# Cortex_M52 register map
Vendor: Arm Ltd.; Series: ARMv8.1-M Mainline; File version: 1.0.0
CPU: other r0p0, little endian, MPU, FPU, double-precision FPU, DSP, 8 interrupt priority bits
Registers are 32-bit, read-write, reset 0x0 unless marked. A register's access mark holds for its fields unless they carry their own. Offsets are from the block's base; [hi:lo] are bit positions; {n}, {i} and the like mark numbered series.

## PMU — Performance Monitoring Unit (ARMv8.1-M): a 32-bit cycle counter and up to 8 (architecturally 31) 16-bit event counters selecting from the PMU event list (instructions, cache refills, branch mispredictions, MVE activity ...), with overflow interrupt/halt.
Base 0xE0003000
{0x0+4i} EVCNTR{i} (i=0..7) — Event Counter n: 16-bit count of the event selected in EVTYPERn. Only NUM_CNTS counters exist (8 on Cortex-M55/M85); the rest read as zero.
  [15:0] CNT — Event count (16 bits on Cortex-M55/M85; an overflow sets OVSSET bit n).
0x7C CCNTR — Cycle Counter: 32-bit processor cycle count while CTRL.ENABLE = 1 and CYCCNT_DISABLE = 0.
  [31:0] CCNT — Cycle count.
{0x400+4i} EVTYPER{i} (i=0..7) — Event Type Register n: the event number counter n counts (see the PMU event list in the core TRM).
  [15:0] EVENTTOCNT — Event number to count. Common events: 0x0000 SW_INCR, 0x0001 L1I_CACHE_REFILL, 0x0003 L1D_CACHE_REFILL, 0x0004 L1D_CACHE, 0x0008 INST_RETIRED, 0x0010 BR_MIS_PRED, 0x0011 CPU_CYCLES, 0x0012 BR_PRED, 0x0014 L1I_CACHE, 0x0023 STALL_FRONTEND, 0x0024 STALL_BACKEND, 0x0100-0x01xx MVE_* (see the core TRM).
0x47C CCFILTR — Cycle Counter Filter Register: reserved (no filtering on M-profile).
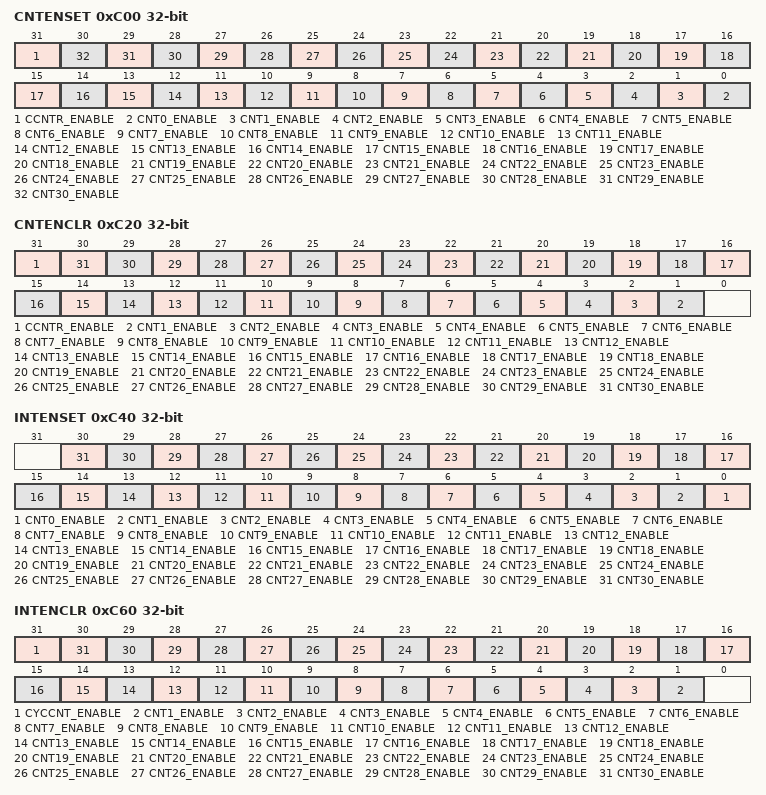
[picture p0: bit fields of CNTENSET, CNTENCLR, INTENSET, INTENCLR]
0xC00 CNTENSET — Count Enable Set Register: write 1 to enable a counter; reads the enable state of every counter.
  [31] CCNTR_ENABLE — Cycle counter: write 1 to enable; reads 1 if enabled.
  [n] CNT{n}_ENABLE (n=0..30) — Event counter {n}: write 1 to enable; reads 1 if enabled.
0xC20 CNTENCLR — Count Enable Clear Register: write 1 to disable a counter; reads the enable state.
  [31] CCNTR_ENABLE — Cycle counter: write 1 to disable; reads 1 if enabled.
  [n] CNT{n}_ENABLE (n=1..30) — Event counter {n}: write 1 to disable; reads 1 if enabled.
0xC40 INTENSET — Interrupt Enable Set Register: write 1 to enable the overflow interrupt/debug event of a counter; reads the enable state.
  [n] CNT{n}_ENABLE (n=0..30) — Event counter {n}: write 1 to enable its overflow interrupt (PMU_IRQ) / debug event; reads 1 if enabled.
0xC60 INTENCLR — Interrupt Enable Clear Register: write 1 to disable the overflow interrupt of a counter.
  [31] CYCCNT_ENABLE — Cycle counter: write 1 to disable its overflow interrupt; reads 1 if enabled.
  [n] CNT{n}_ENABLE (n=1..30) — Event counter {n}: write 1 to disable its overflow interrupt; reads 1 if enabled.
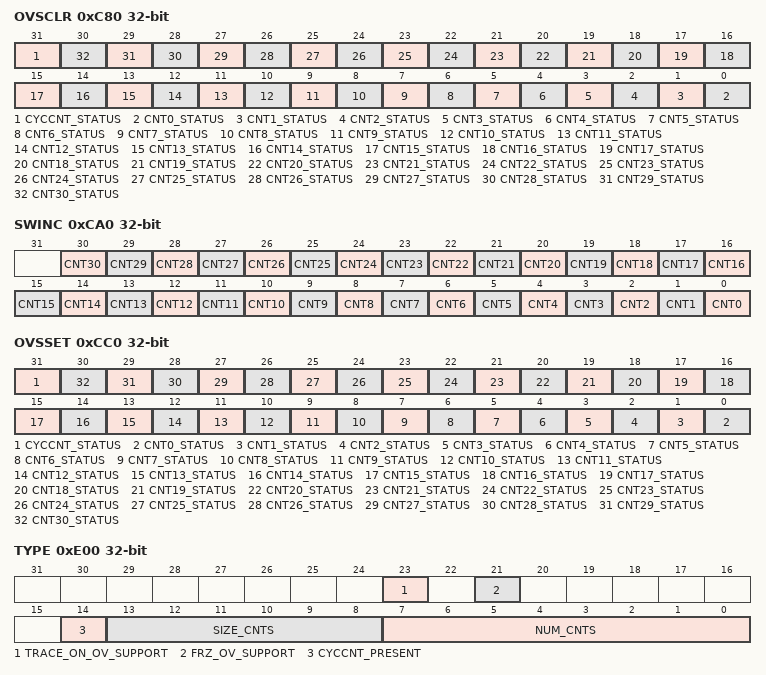
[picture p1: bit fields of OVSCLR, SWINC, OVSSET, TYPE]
0xC80 OVSCLR — Overflow Flag Status Clear Register: reads the overflow flags; write 1 to clear a flag.
  [31] CYCCNT_STATUS — Cycle counter overflowed; write 1 to clear the flag.
  [n] CNT{n}_STATUS (n=0..30) — Event counter {n} overflowed; write 1 to clear the flag.
0xCA0 SWINC — Software Increment Register: write 1 to increment a counter that is counting the SW_INCR event (0x0000).
  [n] CNT{n} (n=0..30) — Write 1 to increment event counter {n} if it counts SW_INCR (event 0x0000).
0xCC0 OVSSET — Overflow Flag Status Set Register: reads the overflow flags; write 1 to set a flag (testing).
  [31] CYCCNT_STATUS — Cycle counter overflow flag; write 1 to set it.
  [n] CNT{n}_STATUS (n=0..30) — Event counter {n} overflow flag; write 1 to set it.
0xE00 TYPE — PMU Type Register: how many counters exist, their size, and which options are supported. Read-only.
  [23] TRACE_ON_OV_SUPPORT — 1 = trace-on-overflow (CTRL.TRACE_ON_OV) is supported.
  [21] FRZ_OV_SUPPORT — 1 = freeze-on-overflow (CTRL.FRZ_ON_OV) is supported.
  [14] CYCCNT_PRESENT — 1 = the cycle counter CCNTR is implemented.
  [13:8] SIZE_CNTS — Event counter size - 1 in bits (15 = 16-bit counters).
  [7:0] NUM_CNTS — Number of event counters implemented (8 on Cortex-M55/M85/M52).
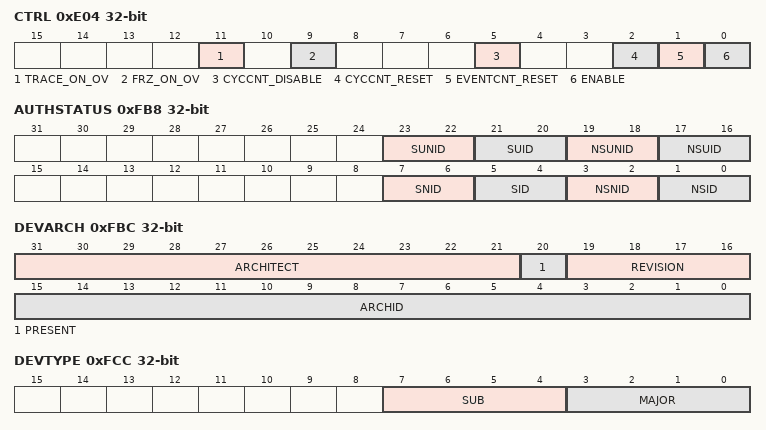
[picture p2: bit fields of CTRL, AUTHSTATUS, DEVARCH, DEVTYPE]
0xE04 CTRL — PMU Control Register: global enable, counter resets, cycle counter disable, freeze/trace on overflow.
  [11] TRACE_ON_OV — Trace on overflow: 1 = a counter overflow emits a trace (ITM/ETM) event.
  [9] FRZ_ON_OV — Freeze on overflow: 1 = all counters stop when any counter overflows, so a snapshot can be read.
  [5] CYCCNT_DISABLE — 1 = the cycle counter is disabled even when ENABLE = 1.
  [2] CYCCNT_RESET — Write 1 to reset CCNTR to 0. Reads as 0.
  [1] EVENTCNT_RESET — Write 1 to reset every event counter to 0. Reads as 0.
  [0] ENABLE — Global enable: 0 = all counters stop (their values are kept).
0xFB8 AUTHSTATUS — Authentication Status Register: which debug/trace permissions currently apply to the PMU.
  [23:22] SUNID — Secure unprivileged non-invasive debug: 2 = disabled, 3 = enabled.
  [21:20] SUID — Secure unprivileged invasive debug: 2 = disabled, 3 = enabled.
  [19:18] NSUNID — Non-secure unprivileged non-invasive debug: 2 = disabled, 3 = enabled.
  [17:16] NSUID — Non-secure unprivileged invasive debug: 2 = disabled, 3 = enabled.
  [7:6] SNID — Secure non-invasive debug: 2 = disabled, 3 = enabled. Counting Secure events requires it.
  [5:4] SID — Secure invasive debug: 2 = disabled, 3 = enabled.
  [3:2] NSNID — Non-secure non-invasive debug: 2 = disabled, 3 = enabled. Counting Non-secure events requires it.
  [1:0] NSID — Non-secure invasive debug: 2 = disabled, 3 = enabled.
0xFBC DEVARCH — Device Architecture Register: CoreSight ARCHID of the PMU (0x0A06 with revision -> 0x2A06).
  [31:21] ARCHITECT — JEP106 code of the architect (Arm: 0x23B).
  [20] PRESENT — 1 = DEVARCH is present and its contents are valid.
  [19:16] REVISION — Architecture revision.
  [15:0] ARCHID — Architecture ID, including the architecture part number [11:0] and revision [15:12].
0xFCC DEVTYPE — Device Type Register: 0x16 (performance monitor, processor core).
  [7:4] SUB — Sub type within the major class.
  [3:0] MAJOR — Major type: 0 miscellaneous, 1 trace sink, 2 trace link, 3 trace source, 4 debug control, 5 debug logic, 6 PMU.
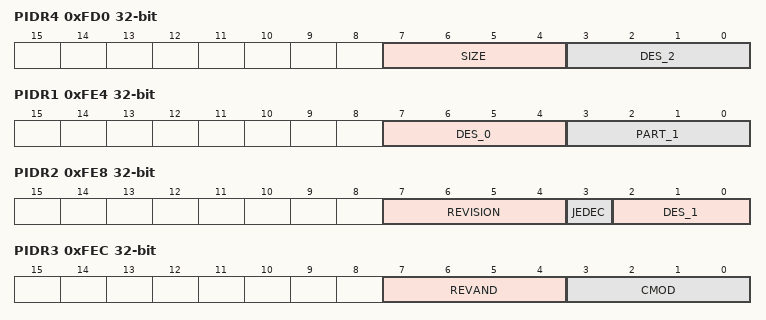
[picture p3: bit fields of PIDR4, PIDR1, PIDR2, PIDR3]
0xFD0 PIDR4 ro — Peripheral Identification Register 4: JEP106 continuation code and component size.
  [7:4] SIZE — Log2 of the number of 4 KB blocks the component occupies (0 = one block).
  [3:0] DES_2 — JEP106 continuation code of the designer (Arm: 0x4).
{0xFC0+4i} PIDR{i} ro (i=5..7) — Peripheral Identification Register {i} (reserved, reads as zero).
0xFE0 PIDR0 ro — Peripheral Identification Register 0: part number bits [7:0].
  [7:0] PART_0 — Part number bits [7:0].
0xFE4 PIDR1 ro — Peripheral Identification Register 1: part number bits [11:8] and designer bits [3:0].
  [7:4] DES_0 — JEP106 identity code bits [3:0] of the designer.
  [3:0] PART_1 — Part number bits [11:8].
0xFE8 PIDR2 ro — Peripheral Identification Register 2: designer bits [6:4], JEDEC flag and revision.
  [7:4] REVISION — Component major revision.
  [3] JEDEC — Always 1: the designer ID is a JEDEC JEP106 code.
  [2:0] DES_1 — JEP106 identity code bits [6:4] of the designer.
0xFEC PIDR3 ro — Peripheral Identification Register 3: customer modified and minor revision.
  [7:4] REVAND — Minor revision (metal fix) number.
  [3:0] CMOD — Customer Modified: 0 if the component has not been modified by the integrator.
0xFF0 CIDR0 ro — Component Identification Register 0: preamble byte 0 (0x0D).
  [7:0] PRMBL_0 — Preamble, reads as 0x0D.
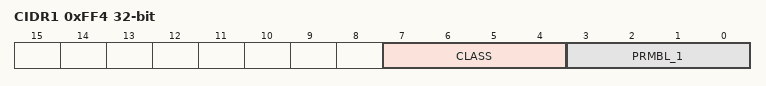
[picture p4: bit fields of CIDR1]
0xFF4 CIDR1 ro — Component Identification Register 1: component class and preamble.
  [7:4] CLASS — Component class: 0x1 ROM table, 0x9 CoreSight component, 0xE generic IP, 0xF CoreLink/PrimeCell.
  [3:0] PRMBL_1 — Preamble, reads as 0x0.
0xFF8 CIDR2 ro — Component Identification Register 2: preamble byte 2 (0x05).
  [7:0] PRMBL_2 — Preamble, reads as 0x05.
0xFFC CIDR3 ro — Component Identification Register 3: preamble byte 3 (0xB1).
  [7:0] PRMBL_3 — Preamble, reads as 0xB1.
